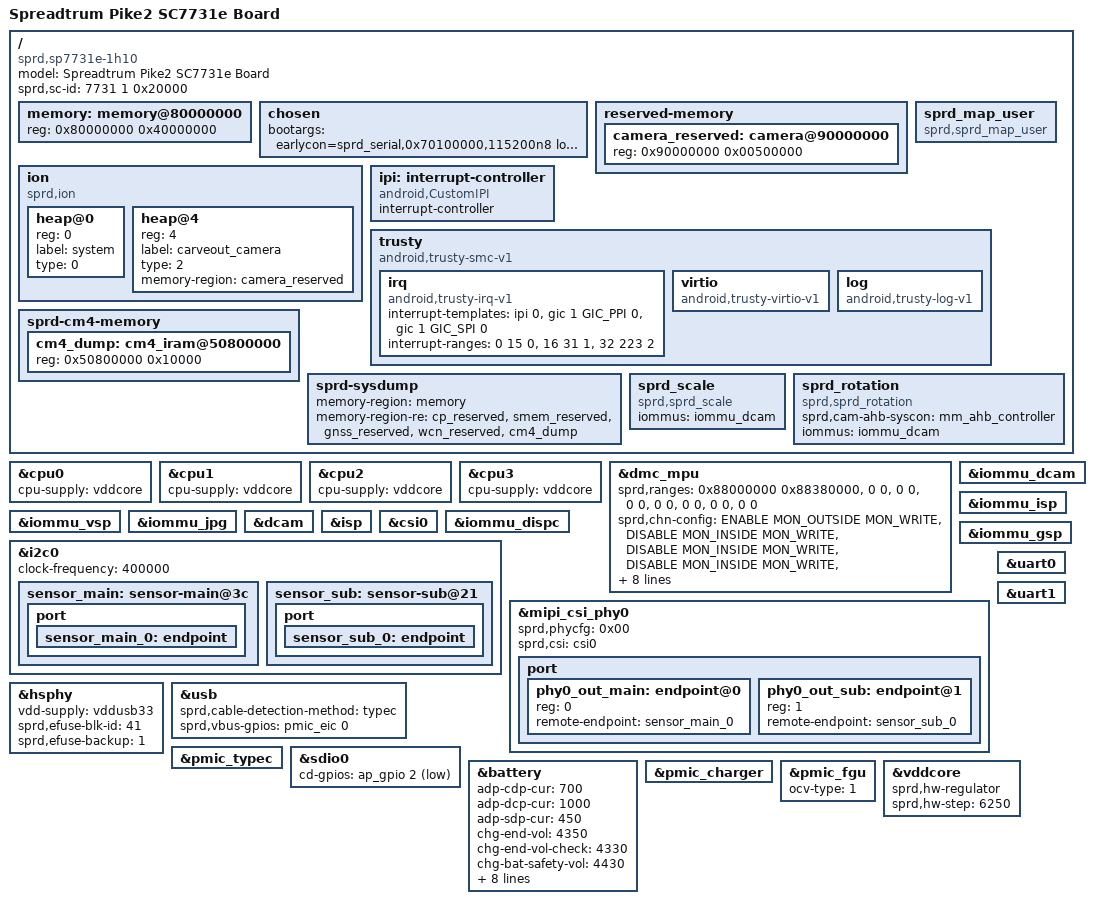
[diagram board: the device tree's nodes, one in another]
/*
 * Spreadtrum Pike2 SP7731e DTS file
 *
 * Copyright (C) 2016-2017, Spreadtrum Communications Inc.
 *
 * This file is licensed under a dual GPLv2 or X11 license.
 */

#include "sc7731e.dtsi"
#include "sp7731e-common.dtsi"

/ {
	model = "Spreadtrum Pike2 SC7731e Board";

	compatible = "sprd,sp7731e-1h10", "sprd,sc7731e";

	sprd,sc-id = <7731 1 0x20000>;

	memory: memory@80000000 {
		device_type = "memory";
		reg = <0x80000000 0x40000000>;
	};

	chosen {
		bootargs = "earlycon=sprd_serial,0x70100000,115200n8 loglevel=1 console=ttyS1,115200n8 init=/init root=/dev/mmcblk0p30 ro rootfstype=ext4 rootwait androidboot.hardware=sp7731e_1h10 androidboot.dtbo_idx=0 nmi_watchdog=panic softlockup_panic=1";
	};

	reserved-memory {
		camera_reserved: camera@90000000{
			reg = <0x90000000 0x00500000>;
		};
	};

	sprd_map_user {
		compatible = "sprd,sprd_map_user";
	};

	ion {
		compatible = "sprd,ion";
		#address-cells = <1>;
		#size-cells = <0>;

		heap@0 {
			reg = <0>;
			label = "system";
			type = <0>;
		};

		heap@4 {
			reg = <4>;
			label = "carveout_camera";
			type = <2>;
			memory-region = <&camera_reserved>;
		};
	};

	ipi: interrupt-controller {
		compatible = "android,CustomIPI";
		#interrupt-cells = <1>;
		interrupt-controller;
	};

	trusty {
		compatible = "android,trusty-smc-v1";

		irq {
			compatible = "android,trusty-irq-v1";
			interrupt-templates = <&ipi 0>,
						<&gic 1 GIC_PPI 0>,
						<&gic 1 GIC_SPI 0>;
			interrupt-ranges = < 0  15 0>,
						<16  31 1>,
						<32 223 2>;
		};

		virtio {
			compatible = "android,trusty-virtio-v1";
		};

		log {
			compatible = "android,trusty-log-v1";
		};
	};

	sprd-cm4-memory {
		#address-cells = <1>;
		#size-cells = <1>;
		ranges;

		cm4_dump: cm4_iram@50800000 {
			reg = <0x50800000 0x10000>;
		};
	};

	sprd-sysdump {
		memory-region = <&memory>;
		memory-region-re = <&cp_reserved>, <&smem_reserved>,
				<&gnss_reserved>, <&wcn_reserved>,
				<&cm4_dump>;
	};

	sprd_scale {
		compatible = "sprd,sprd_scale";
		iommus = <&iommu_dcam>;
		status = "okay";
	};

	sprd_rotation {
		compatible = "sprd,sprd_rotation";
		sprd,cam-ahb-syscon = <&mm_ahb_controller>;
		iommus = <&iommu_dcam>;
		status = "okay";
	};
};

&cpu0 {
	cpu-supply = <&vddcore>;
};

&cpu1 {
	cpu-supply = <&vddcore>;
};

&cpu2 {
	cpu-supply = <&vddcore>;
};

&cpu3 {
	cpu-supply = <&vddcore>;
};

&dmc_mpu {
	status = "okay";
	sprd,ranges = <0x88000000 0x88380000>,
		      <0 0>,
		      <0 0>,
		      <0 0>,
		      <0 0>,
		      <0 0>,
		      <0 0>,
		      <0 0>;
	sprd,chn-config =
			<ENABLE MON_OUTSIDE MON_WRITE>,
			<DISABLE MON_INSIDE MON_WRITE>,
			<DISABLE MON_INSIDE MON_WRITE>,
			<DISABLE MON_INSIDE MON_WRITE>,
			<DISABLE MON_INSIDE MON_WRITE>,
			<DISABLE MON_INSIDE MON_WRITE>,
			<DISABLE MON_INSIDE MON_WRITE>,
			<DISABLE MON_INSIDE MON_WRITE>;
	sprd,id-config =
			<USERID 0xc0 0xc0>, <MPUID 0 0>,
			<MPUID 0 0>, <MPUID 0 0>,
			<MPUID 0 0>, <MPUID 0 0>,
			<MPUID 0 0>, <MPUID 0 0>;
	sprd,panic;
};

&iommu_dcam {
	status = "okay";
};

&iommu_isp {
	status = "okay";
};

&iommu_vsp {
	status = "okay";
};

&iommu_jpg {
	status = "okay";
};

&dcam {
	status = "okay";
};

&isp {
	status = "okay";
};

&csi0 {
	status = "okay";
};

&iommu_dispc {
	status = "okay";
};

&iommu_gsp {
	status = "okay";
};

&i2c0 {
	status = "okay";
	clock-frequency = <400000>;

	sensor_main: sensor-main@3c {
		port {
			sensor_main_0: endpoint {
			};
		};
	};

	sensor_sub: sensor-sub@21 {
		port {
			sensor_sub_0: endpoint {
			};
		};
	};
};

&mipi_csi_phy0 {
	status = "okay";
	sprd,phycfg = <0x00>;
	sprd,csi = <&csi0>;
	port {
		#address-cells = <1>;
		#size-cells = <0>;
		phy0_out_main: endpoint@0 {
			reg = <0>;
			remote-endpoint = <&sensor_main_0>;
		};
		phy0_out_sub: endpoint@1 {
			reg = <1>;
			remote-endpoint = <&sensor_sub_0>;
		};
	};
};

&uart0 {
	status = "okay";
};

&uart1 {
	status = "okay";
};

&hsphy {
	vdd-supply = <&vddusb33>;
	sprd,efuse-blk-id = <41>;
	sprd,efuse-backup = <1>;
};

&usb {
	sprd,cable-detection-method = "typec";
	sprd,vbus-gpios = <&pmic_eic 0 0>;
};

&pmic_typec {
	status = "okay";
};

&sdio0 {
	cd-gpios = <&ap_gpio 2 1>;
};

&battery {
	adp-cdp-cur = <700>;
	adp-dcp-cur = <1000>;
	adp-sdp-cur = <450>;
	chg-end-vol = <4350>;
	chg-end-vol-check = <4330>;
	chg-bat-safety-vol = <4430>;
	rechg-vol = <4270>;
	rsense-real = <200>;
	rint = <320>;
	cnom = <2780>;
	ocv-tab-vol = <4340 4243 4185 4132 4083 4037 3996
			3959 3921 3876 3842 3818 3800 3786
			3776 3768 3753 3731 3696 3663 3400>;
	ocv-tab-cap = <100  95   90   85   80   75   70
			65   60   55   50   45   40   35
			30   25   20   15   10   5    0>;
};

&pmic_charger {
	status = "okay";
};

&pmic_fgu {
	ocv-type = <1>;
};

&vddcore {
	sprd,hw-regulator;
	sprd,hw-step = <6250>;
};
